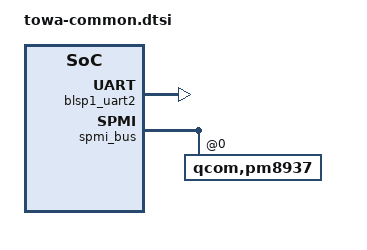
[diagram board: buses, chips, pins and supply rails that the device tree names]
/*
 * Copyright (c) 2015-2016, The Linux Foundation. All rights reserved.
 *
 * This program is free software; you can redistribute it and/or modify
 * it under the terms of the GNU General Public License version 2 and
 * only version 2 as published by the Free Software Foundation.
 *
 * This program is distributed in the hope that it will be useful,
 * but WITHOUT ANY WARRANTY; without even the implied warranty of
 * MERCHANTABILITY or FITNESS FOR A PARTICULAR PURPOSE.  See the
 * GNU General Public License for more details.
 */

#include "towa-bq2560x.dtsi"
#include "towa-vibrate.dtsi"
#include "towa-gpio-led.dtsi"
#include "towa-sdhc.dtsi"

&blsp1_uart2 {
	status = "ok";
	pinctrl-names = "default";
	pinctrl-0 = <&uart_console_active>;
};

&soc {
        qcom,rmtfs_sharedmem@00000000 {
                reg = <0x00000000 0x00400000>;
        };
};

&spmi_bus {
	qcom,pm8937@0 {
		qcom,power-on@800 {
			qcom,s3-src = "kpdpwr";
			qcom,s3-debounce = <8>;
		};
	};
};
